# ESP32-S31 register map
Vendor: ESPRESSIF SYSTEMS (SHANGHAI) CO., LTD.; Series: ESP32 S-Series; File version: 1
CPU: RV32IMAFC r0p0, little endian, no MPU, FPU, 0 interrupt priority bits
Address unit: 32 bits
Registers are 32-bit, read-write, reset 0x0 unless marked. A register's access mark holds for its fields unless they carry their own. Offsets are from the block's base; [hi:lo] are bit positions; {n}, {i} and the like mark numbered series.

## SHA — SHA (Secure Hash Algorithm) Accelerator
Base 0x20509000
0x00 MODE reset 0x2 — Configures SHA algorithm
  [3:0] MODE — Configures the SHA algorithm. \\ 0: SHA-1\\ 1: SHA2-224\\ 2: SHA2-256\\ 3: SHA2-384\\ 4: SHA2-512\\ 5: SHA2-512/224\\ 6: SHA2-512/256\\ 7: SHA2-512/t\\ 8: SHA3-224\\ 9: SHA3-256\\ 10: SHA3-384\\ 11: SHA3-512\\ 12: SHAKE128\\ 13: SHAKE256\\ 14: SM3\\
0x04 T_STRING — SHA 512/t configuration register 0.
  [31:0] T_STRING — Sha t_string (used if and only if mode == SHA_512/t).
0x08 T_LENGTH — SHA 512/t configuration register 1.
  [6:0] T_LENGTH — Sha t_length (used if and only if mode == SHA_512/t).
0x0C DMA_BLOCK_NUM — Block number register (only effective for DMA-SHA)
  [15:0] DMA_BLOCK_NUM — Configures the DMA-SHA block number.
0x10 START wo — Starts the SHA accelerator for Typical SHA operation
  [0] START — Write 1 to start Typical SHA calculation.
0x14 CONTINUE wo — Continues SHA operation (only effective in Typical SHA mode)
  [0] CONTINUE — Write 1 to continue Typical SHA calculation.
0x18 BUSY ro — Represents if SHA Accelerator is busy or not
  [0] STATE — Represents the states of SHA accelerator. \\ 0: idle\\ 1: busy\\
0x1C DMA_START wo — Starts the SHA accelerator for DMA-SHA operation
  [0] DMA_START — Write 1 to start DMA-SHA calculation.
0x20 DMA_CONTINUE wo — Continues SHA operation (only effective in DMA-SHA mode)
  [0] DMA_CONTINUE — Write 1 to continue DMA-SHA calculation.
0x24 CLEAR_IRQ wo — DMA-SHA interrupt clear register
  [0] CLEAR_INTERRUPT — Write 1 to clear DMA-SHA interrupt.
0x28 IRQ_ENA — DMA-SHA interrupt enable register
  [0] INTERRUPT_ENA — Write 1 to enable DMA-SHA interrupt.
0x2C DATE reset 0x20250623 — Version control register
  [29:0] DATE — Version control register.
0x30 DMA_RX_RESET wo — DMA RX FIFO Reset Signal
  [0] DMA_RX_RESET — Write 1 to reset DMA RX FIFO
0x34 DMA_TX_RESET wo — DMA TX FIFO Reset Signal
  [0] DMA_TX_RESET — Write 1 to reset DMA TX FIFO
0x38 FREE reset 0x1 — SHA free state
  [0] FREE — Represents if SHA Accelerator is free or not. \\ 0: non-free\\ 1: free\\
0x3C _3_SHAKE_LENGTH reset 0x32 — DMA configuration register 3.
  [20:0] _3_SHAKE_LENGTH — SHAKE output hash word length
{0x40+i} _2_SM_3_H_MEM[{i}] (i=0..63) 8-bit access not given — SHA1, SHA2-256, SM3 H memory which contains intermediate hash or final hash. \\ SHA1, SHA2-256, SM3 : 0x00~0x20 (R/W) \\ SHA2-512 : 0x00~0x40 (R/W) \\
{0x80+i} _2_SM_3_M_MEM[{i}] (i=0..127) 8-bit access not given — SHA1, SHA2-256, SM3 M memory which contains message. \\ SHA1, SHA2-256, SM3 : 0x00~0x40 \\ SHA2-512 : 0x00~0x80 \\
{0x100+i} _3_H_MEM[{i}] (i=0..199) 8-bit access not given — SHA3, SHAKE H memory which contains intermediate hash or final hash.
{0x200+i} _3_M_MEM[{i}] (i=0..199) 8-bit access not given — SHA3, SHAKE M memory which contains message.

## TEE — TEE Peripheral
Base 0x20504000
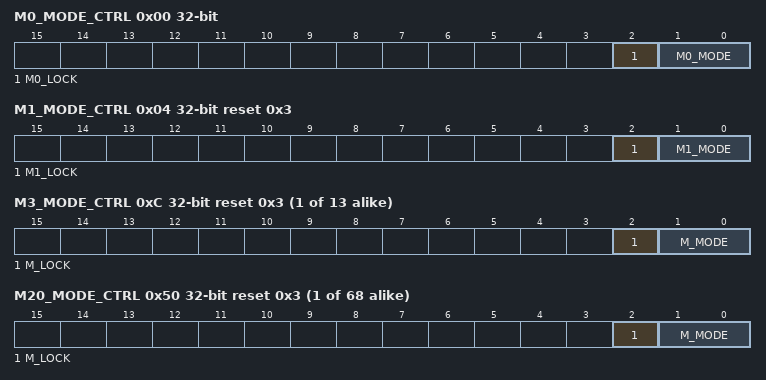
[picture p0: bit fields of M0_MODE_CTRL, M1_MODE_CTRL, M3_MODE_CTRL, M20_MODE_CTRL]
0x00 M0_MODE_CTRL — TEE mode control register
  [2] M0_LOCK — Set 1 to lock m0 tee configuration
  [1:0] M0_MODE — Configures M0 security level mode.\\ 0: tee_mode \\ 1: ree_mode0 \\ 2: ree_mode1 \\ 3: ree_mode2 \\
0x04 M1_MODE_CTRL reset 0x3 — TEE mode control register
  [2] M1_LOCK — Set 1 to lock m1 tee configuration
  [1:0] M1_MODE — Configures M0 security level mode.\\ 0: tee_mode \\ 1: ree_mode0 \\ 2: ree_mode1 \\ 3: ree_mode2 \\
{0x0+4i} M{i}_MODE_CTRL (i=3..15) reset 0x3 — TEE mode control register
  [2] M_LOCK — Set 1 to lock m3 tee configuration
  [1:0] M_MODE — Configures M%s security level mode.\\ 0: tee_mode \\ 1: ree_mode0 \\ 2: ree_mode1 \\ 3: ree_mode2 \\
{0x0+4i} M{i}_MODE_CTRL (i=20..87) reset 0x3 — TEE mode control register
  [2] M_LOCK — Set 1 to lock m20 tee configuration
  [1:0] M_MODE — Configures M%s security level mode.\\ 0: tee_mode \\ 1: ree_mode0 \\ 2: ree_mode1 \\ 3: ree_mode2 \\
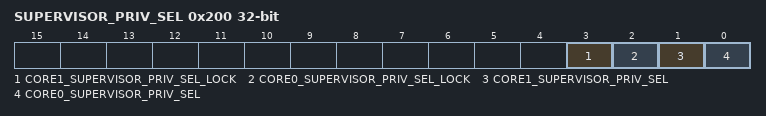
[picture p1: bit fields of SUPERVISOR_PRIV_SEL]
0x200 SUPERVISOR_PRIV_SEL — TEE mode control register
  [3] CORE1_SUPERVISOR_PRIV_SEL_LOCK — Set 1 to lock reg_core1_supervisor_priv_sel configuration
  [2] CORE0_SUPERVISOR_PRIV_SEL_LOCK — Set 1 to lock reg_core0_supervisor_priv_sel configuration
  [1] CORE1_SUPERVISOR_PRIV_SEL — Configures the privilege of the core0 supervisor mode .\\ 0: same as user_mode \\ 1: same as machine_mode \\
  [0] CORE0_SUPERVISOR_PRIV_SEL — Configures the privilege of the core0 supervisor mode .\\ 0: same as user_mode \\ 1: same as machine_mode \\
0x3F8 CLOCK_GATE reset 0x1 — Clock gating register
  [0] CLK_EN — Configures whether to keep the clock always on.\\ 0: enable automatic clock gating \\ 1: keep the clock always on \\
0x3FC DATE reset 0x2506250 — Version control register
  [27:0] DATE
